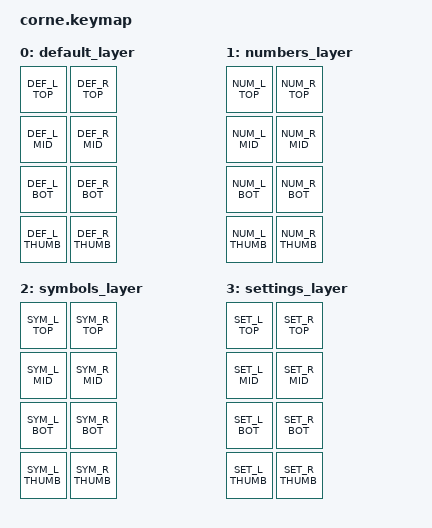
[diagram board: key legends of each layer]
/*
 * Copyright (c) 2020 The ZMK Contributors
 * SPDX-License-Identifier: MIT
 */

#include <behaviors.dtsi>
#include <dt-bindings/zmk/bt.h>
#include <dt-bindings/zmk/keys.h>

#include "shared_keymap.dtsi"

/ {
    combos {
        compatible = "zmk,combos";

        settings_layer {
            bindings = <&mo LAYER_SETTINGS>;
            key-positions = <37 40>;
        };

        delete {
            bindings = <&kp DEL>;
            key-positions = <11 41>;
        };
    };

    keymap {
        compatible = "zmk,keymap";

        default_layer {
            // -----------------------------------------------------------------------------------------
            // |  TAB |  Q  |  W  |  E  |  R  |  T  |   |  Y  |  U   |  I  |  O  |  P  | BSPC |
            // | CTRL |  A  |  S  |  D  |  F  |  G  |   |  H  |  J   |  K  |  L  |  ;  |  '   |
            // | SHFT |  Z  |  X  |  C  |  V  |  B  |   |  N  |  M   |  ,  |  .  |  /  | ESC  |
            //                    | GUI | LWR | SPC |   | ENT | RSE  | ALT |
            bindings = <
                DEF_L_TOP    DEF_R_TOP
                DEF_L_MID    DEF_R_MID
                DEF_L_BOT    DEF_R_BOT
                DEF_L_THUMB  DEF_R_THUMB
            >;
        };

        numbers_layer {
            bindings = <
                NUM_L_TOP    NUM_R_TOP
                NUM_L_MID    NUM_R_MID
                NUM_L_BOT    NUM_R_BOT
                NUM_L_THUMB  NUM_R_THUMB
            >;
        };

        symbols_layer {
            bindings = <
                SYM_L_TOP    SYM_R_TOP
                SYM_L_MID    SYM_R_MID
                SYM_L_BOT    SYM_R_BOT
                SYM_L_THUMB  SYM_R_THUMB
            >;
        };

        settings_layer {
            bindings = <
                SET_L_TOP    SET_R_TOP
                SET_L_MID    SET_R_MID
                SET_L_BOT    SET_R_BOT
                SET_L_THUMB  SET_R_THUMB
            >;
        };
    };
};
